# PIC32MM0064GPM064 device description
Architecture: MIPS; Family: PIC32MM1387; Series: PIC32MM
Registers are 32-bit, read-write, no defined reset value unless marked. A register's access mark holds for its fields unless they carry their own. Offsets are from the block's base; [hi:lo] are bit positions; {n}, {i} and the like mark numbered series.

## GPIO
Instances: GPIO 0x1f802910 in periph0
0xF0 RPCON
  [11] IOLOCK
0x110 RPINR1
  [4:0] INT4R
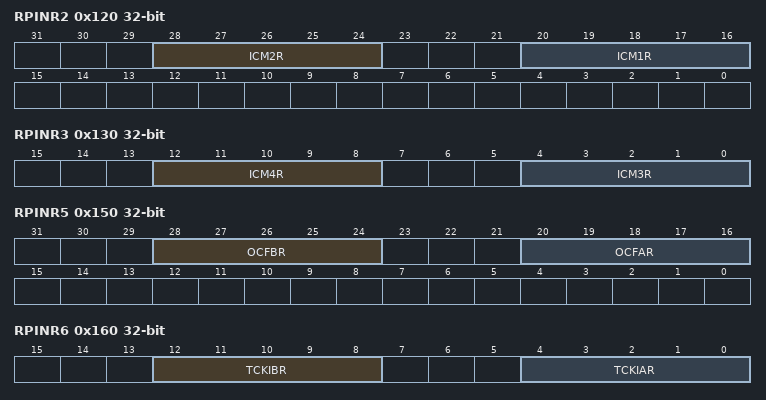
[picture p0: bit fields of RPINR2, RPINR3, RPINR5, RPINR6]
0x120 RPINR2
  [28:24] ICM2R, [20:16] ICM1R
0x130 RPINR3
  [12:8] ICM4R, [4:0] ICM3R
0x150 RPINR5
  [28:24] OCFBR, [20:16] OCFAR
0x160 RPINR6
  [12:8] TCKIBR, [4:0] TCKIAR
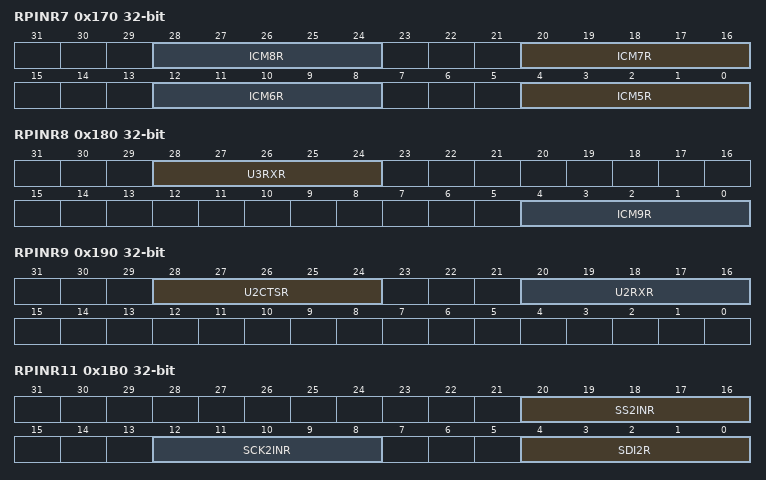
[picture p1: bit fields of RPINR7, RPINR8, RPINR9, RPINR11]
0x170 RPINR7
  [8n-36:8n-40] ICM{n}R (n=5..8)
0x180 RPINR8
  [28:24] U3RXR, [4:0] ICM9R
0x190 RPINR9
  [28:24] U2CTSR, [20:16] U2RXR
0x1A0 RPINR10
  [28:24] U3CTSR
0x1B0 RPINR11
  [20:16] SS2INR, [12:8] SCK2INR, [4:0] SDI2R
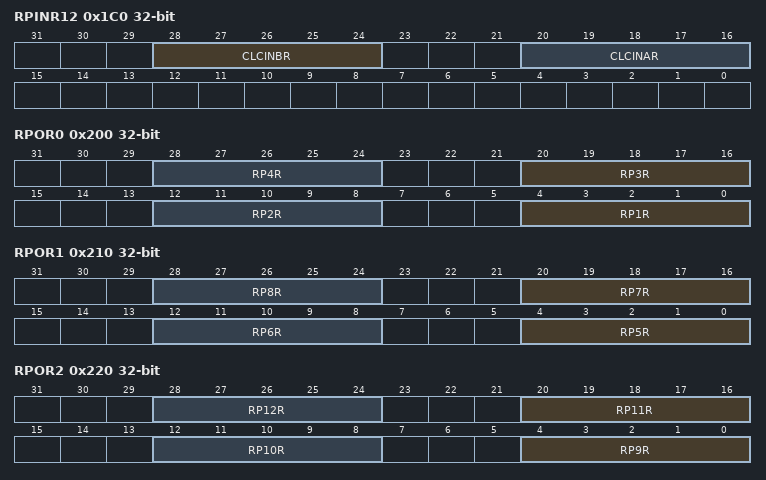
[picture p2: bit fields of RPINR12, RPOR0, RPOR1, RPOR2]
0x1C0 RPINR12
  [28:24] CLCINBR, [20:16] CLCINAR
0x200 RPOR0
  [8n-4:8n-8] RP{n}R (n=1..4)
0x210 RPOR1
  [8n-36:8n-40] RP{n}R (n=5..8)
0x220 RPOR2
  [8n-68:8n-72] RP{n}R (n=9..12)
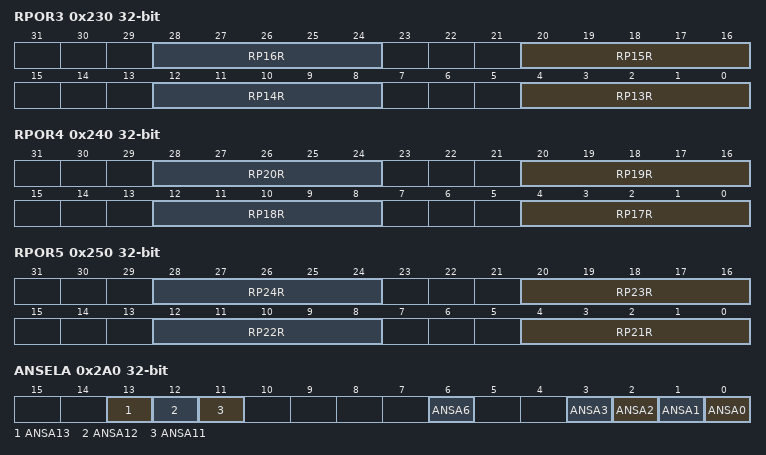
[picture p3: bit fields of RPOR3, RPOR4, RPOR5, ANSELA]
0x230 RPOR3
  [8n-100:8n-104] RP{n}R (n=13..16)
0x240 RPOR4
  [8n-132:8n-136] RP{n}R (n=17..20)
0x250 RPOR5
  [8n-164:8n-168] RP{n}R (n=21..24)
0x2A0 ANSELA
  [13] ANSA13, [12] ANSA12, [11] ANSA11, [6] ANSA6, [n] ANSA{n} (n=0..3)
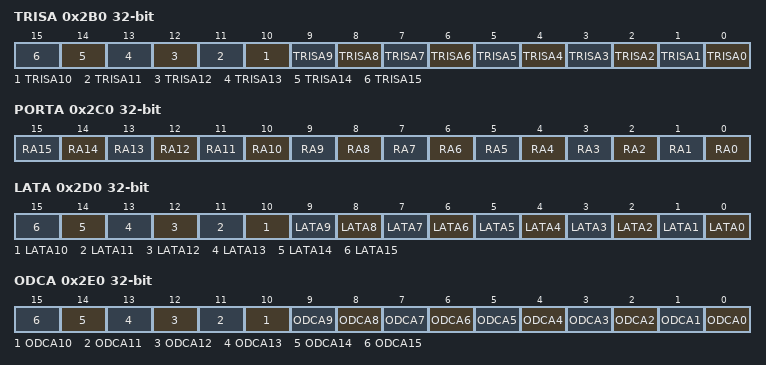
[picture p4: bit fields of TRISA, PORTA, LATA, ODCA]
0x2B0 TRISA
  [n] TRISA{n} (n=0..15)
0x2C0 PORTA
  [n] RA{n} (n=0..15)
0x2D0 LATA
  [n] LATA{n} (n=0..15)
0x2E0 ODCA
  [n] ODCA{n} (n=0..15)
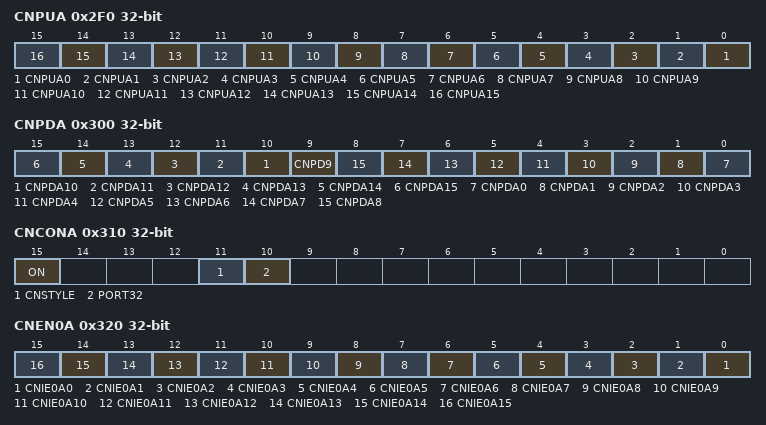
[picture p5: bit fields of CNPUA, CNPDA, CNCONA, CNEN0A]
0x2F0 CNPUA
  [n] CNPUA{n} (n=0..15)
0x300 CNPDA
  [n] CNPDA{n} (n=10..15), [9] CNPD9, [n] CNPDA{n} (n=0..8)
0x310 CNCONA
  [15] ON, [11] CNSTYLE, [10] PORT32
0x320 CNEN0A
  [n] CNIE0A{n} (n=0..15)
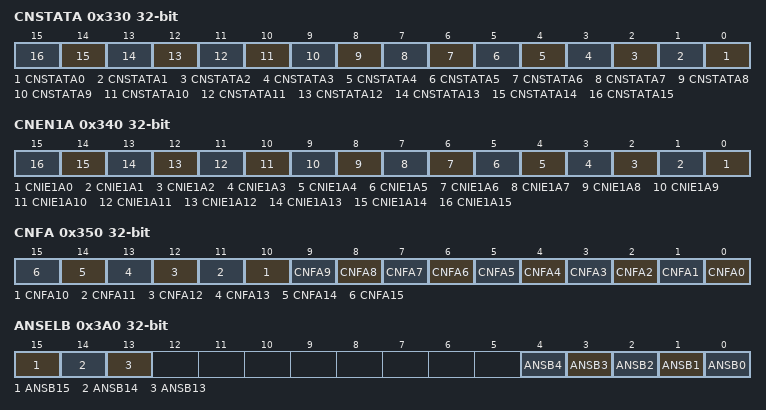
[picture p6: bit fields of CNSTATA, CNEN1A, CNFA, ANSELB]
0x330 CNSTATA
  [n] CNSTATA{n} (n=0..15)
0x340 CNEN1A
  [n] CNIE1A{n} (n=0..15)
0x350 CNFA
  [n] CNFA{n} (n=0..15)
0x360 SR0A
0x370 SR1A
0x3A0 ANSELB
  [15] ANSB15, [14] ANSB14, [13] ANSB13, [n] ANSB{n} (n=0..4)
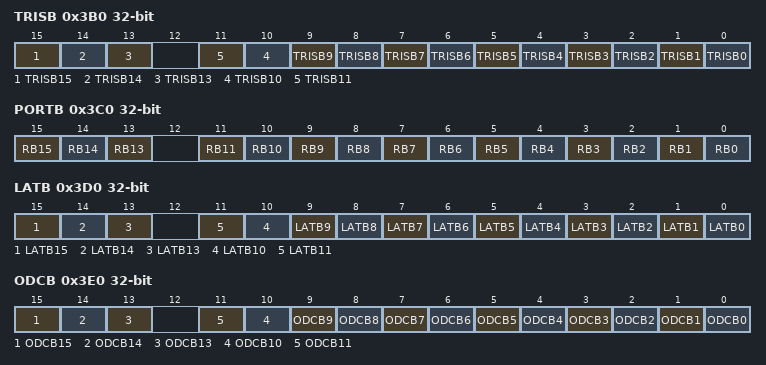
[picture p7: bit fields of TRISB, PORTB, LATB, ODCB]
0x3B0 TRISB
  [15] TRISB15, [14] TRISB14, [13] TRISB13, [n] TRISB{n} (n=0..11)
0x3C0 PORTB
  [15] RB15, [14] RB14, [13] RB13, [n] RB{n} (n=0..11)
0x3D0 LATB
  [15] LATB15, [14] LATB14, [13] LATB13, [n] LATB{n} (n=0..11)
0x3E0 ODCB
  [15] ODCB15, [14] ODCB14, [13] ODCB13, [n] ODCB{n} (n=0..11)
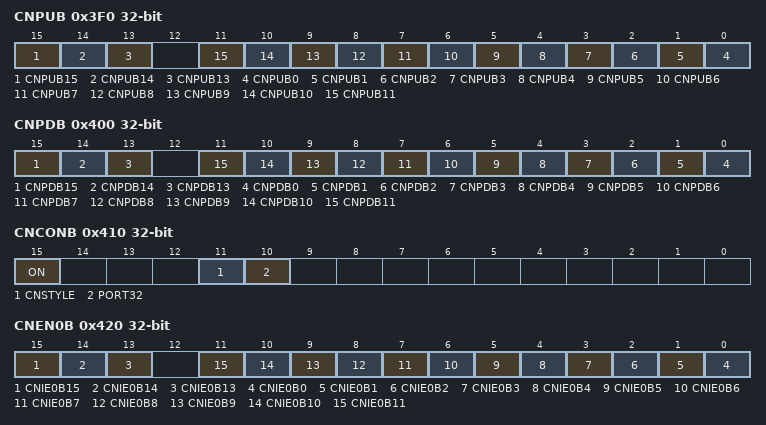
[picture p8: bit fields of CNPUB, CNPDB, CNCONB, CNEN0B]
0x3F0 CNPUB
  [15] CNPUB15, [14] CNPUB14, [13] CNPUB13, [n] CNPUB{n} (n=0..11)
0x400 CNPDB
  [15] CNPDB15, [14] CNPDB14, [13] CNPDB13, [n] CNPDB{n} (n=0..11)
0x410 CNCONB
  [15] ON, [11] CNSTYLE, [10] PORT32
0x420 CNEN0B
  [15] CNIE0B15, [14] CNIE0B14, [13] CNIE0B13, [n] CNIE0B{n} (n=0..11)
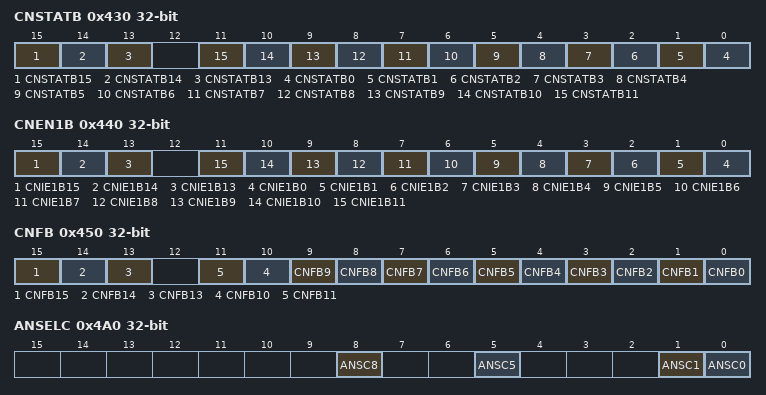
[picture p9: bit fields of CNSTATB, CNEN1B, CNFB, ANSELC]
0x430 CNSTATB
  [15] CNSTATB15, [14] CNSTATB14, [13] CNSTATB13, [n] CNSTATB{n} (n=0..11)
0x440 CNEN1B
  [15] CNIE1B15, [14] CNIE1B14, [13] CNIE1B13, [n] CNIE1B{n} (n=0..11)
0x450 CNFB
  [15] CNFB15, [14] CNFB14, [13] CNFB13, [n] CNFB{n} (n=0..11)
0x460 SR0B
0x470 SR1B
0x4A0 ANSELC
  [8] ANSC8, [5] ANSC5, [1] ANSC1, [0] ANSC0
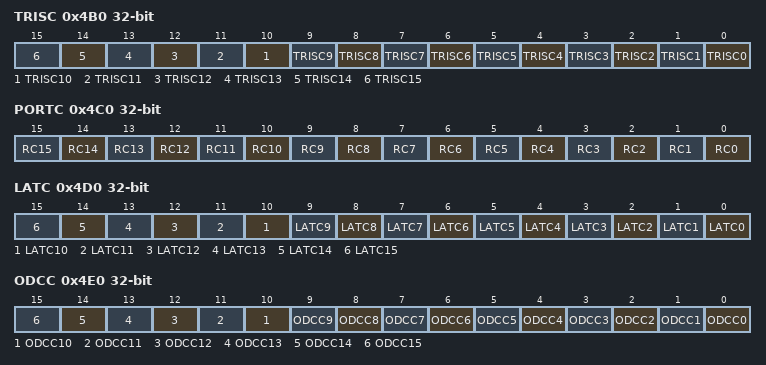
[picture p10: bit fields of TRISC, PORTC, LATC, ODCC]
0x4B0 TRISC
  [n] TRISC{n} (n=0..15)
0x4C0 PORTC
  [n] RC{n} (n=0..15)
0x4D0 LATC
  [n] LATC{n} (n=0..15)
0x4E0 ODCC
  [n] ODCC{n} (n=0..15)
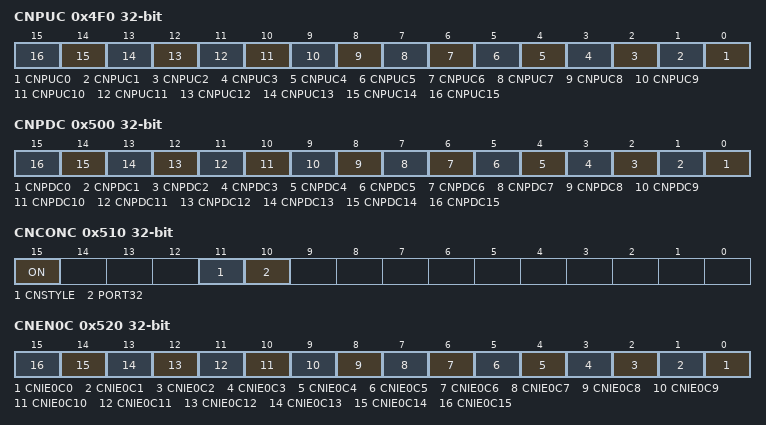
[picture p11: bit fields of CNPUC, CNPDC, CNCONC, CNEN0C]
0x4F0 CNPUC
  [n] CNPUC{n} (n=0..15)
0x500 CNPDC
  [n] CNPDC{n} (n=0..15)
0x510 CNCONC
  [15] ON, [11] CNSTYLE, [10] PORT32
0x520 CNEN0C
  [n] CNIE0C{n} (n=0..15)
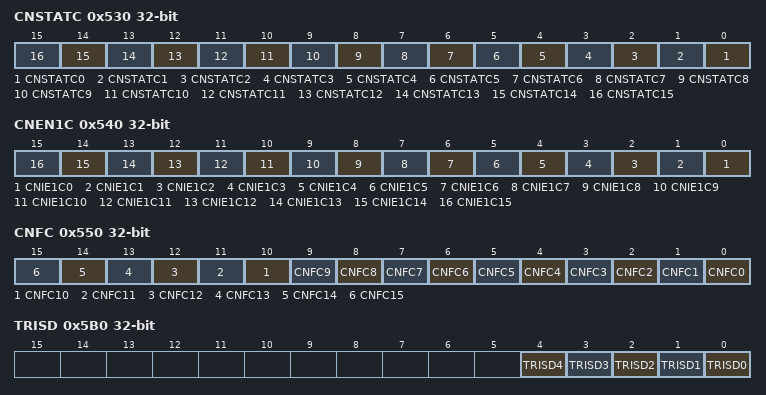
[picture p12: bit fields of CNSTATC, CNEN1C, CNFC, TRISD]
0x530 CNSTATC
  [n] CNSTATC{n} (n=0..15)
0x540 CNEN1C
  [n] CNIE1C{n} (n=0..15)
0x550 CNFC
  [n] CNFC{n} (n=0..15)
0x560 SR0C ro
0x570 SR1C ro
0x5A0 ANSELD ro
0x5B0 TRISD
  [n] TRISD{n} (n=0..4)
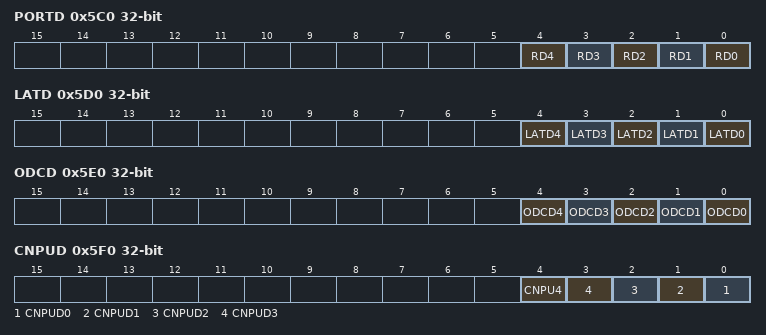
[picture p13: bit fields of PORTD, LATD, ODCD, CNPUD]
0x5C0 PORTD
  [n] RD{n} (n=0..4)
0x5D0 LATD
  [n] LATD{n} (n=0..4)
0x5E0 ODCD
  [n] ODCD{n} (n=0..4)
0x5F0 CNPUD
  [4] CNPU4, [n] CNPUD{n} (n=0..3)
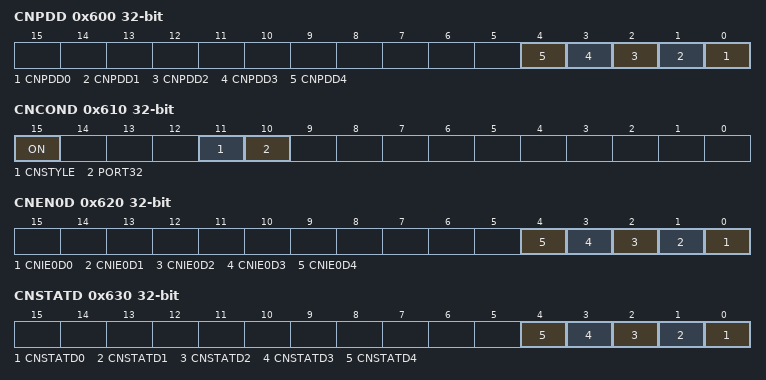
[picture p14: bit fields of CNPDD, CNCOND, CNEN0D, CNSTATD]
0x600 CNPDD
  [n] CNPDD{n} (n=0..4)
0x610 CNCOND
  [15] ON, [11] CNSTYLE, [10] PORT32
0x620 CNEN0D
  [n] CNIE0D{n} (n=0..4)
0x630 CNSTATD
  [n] CNSTATD{n} (n=0..4)
0x640 CNEN1D
  [n] CNIE1D{n} (n=0..4)
0x650 CNFD
  [n] CNFD{n} (n=0..4)
0x660 SR0D ro
0x670 SR1D ro

## HLVD
Instances: HLVD 0x1f802920 in periph0
0x00 HLVDCON — High/Low-Voltage Detect Control Register
  [15] ON — HLVD Module Enable bit
    1=HLVD module is enabled; 0=HLVD module is disabled
  [13] SIDL
  [11] VDIR — Voltage Change Direction Select bit
    1=Event occurs when voltage equals or exceeds the trip point (HLVDL); 0=Event occurs when voltage equals or falls below the trip point (HLVDL)
  [10] BGVST — Band Gap Reference Voltages Stable Status bit
    1=Indicates internal band gap voltage references is stable; 0=Indicates internal band gap voltage reference is not stable
  [9] IRVST — Internal Reference Voltage Stable Status bit
    1=Indicates internal reference voltage references is stable; 0=Indicates internal reference voltage reference is not stable
  [8] HLVDET — High/Low-Voltage Detection Event Status bit
    1=Indicates HLVD Event interrupt is active; 0=Indicates HLVD Event interrupt is not active
  [3:0] HLVDL — High/Low-Voltage Detection Limit Select bits
    15=External LVDIN pin; 14=VDD trip point is between 2.00V and 2.22V; 13=VDD trip point is between 2.08V and 2.33V; 12=VDD trip point is between 2.15V and 2.44V; 11=VDD trip point is between 2.25V and 2.55V; 10=VDD trip point is between 2.35V and 2.69V; 9=VDD trip point is between 2.45V and 2.80V; 8=VDD trip point is between 2.65V and 2.98V; 7=VDD trip point is between 2.75V and 3.09V; 6=VDD trip point is between 2.95V and 3.30V; 5=VDD trip point is between 3.25V and 3.63V; {v}=Reserved; do not use (v=0..4)
